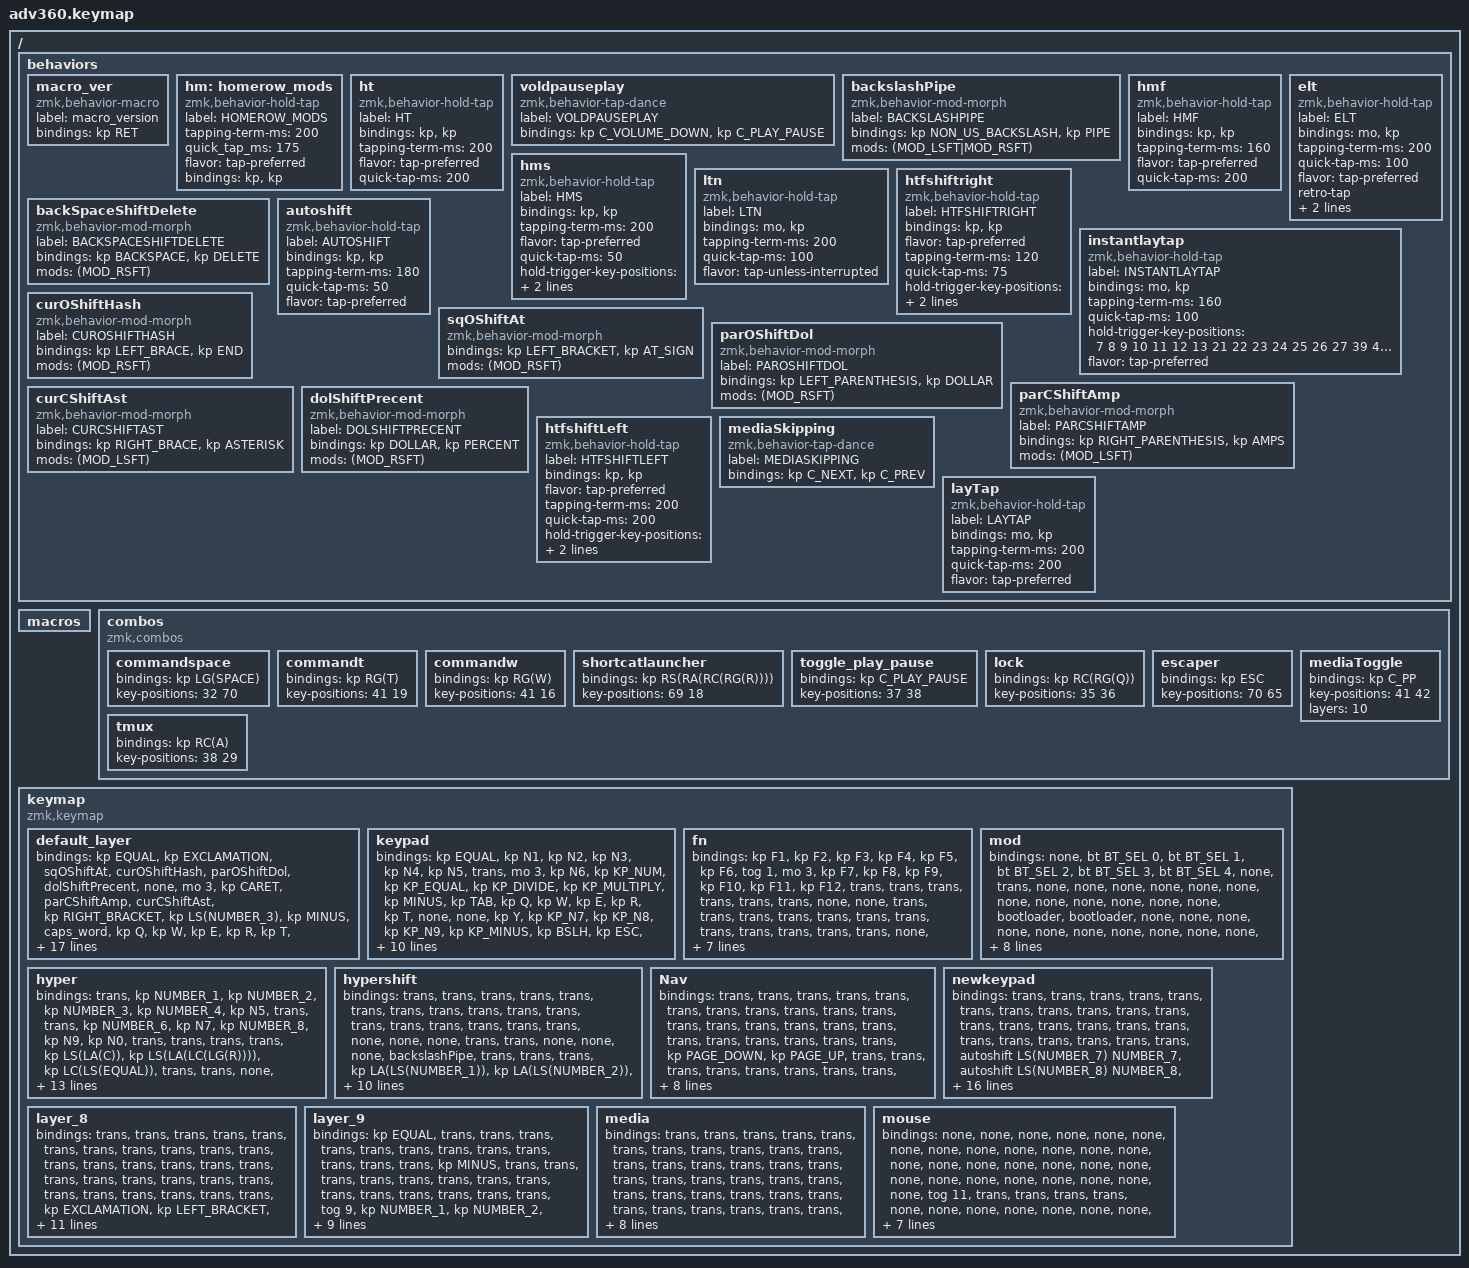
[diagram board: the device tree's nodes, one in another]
#define ZMK_POINTING_DEFAULT_MOVE_VAL 1200  // default: 600
#define ZMK_POINTING_DEFAULT_SCRL_VAL 20 // default: 10

#include <behaviors.dtsi>
#include <dt-bindings/zmk/backlight.h>
#include <dt-bindings/zmk/bt.h>
#include <dt-bindings/zmk/keys.h>
#include <dt-bindings/zmk/pointing.h>
#include <dt-bindings/zmk/rgb.h>

/ {
    behaviors {
        #include "macros.dtsi"
      #include "version.dtsi"
      #ifndef VERSION_MACRO

        macro_ver: macro_ver {
            compatible = "zmk,behavior-macro";
            label = "macro_version";
            #binding-cells = <0>;
            bindings = <&kp RET>;
        };

        #endif

        hm: homerow_mods {
            compatible = "zmk,behavior-hold-tap";
            label = "HOMEROW_MODS";
            #binding-cells = <2>;
            tapping-term-ms = <200>;
            quick_tap_ms = <175>;
            flavor = "tap-preferred";
            bindings = <&kp>, <&kp>;
        };

        ht: ht {
            compatible = "zmk,behavior-hold-tap";
            label = "HT";
            bindings = <&kp>, <&kp>;

            #binding-cells = <2>;
            tapping-term-ms = <200>;
            flavor = "tap-preferred";
            quick-tap-ms = <200>;
        };

        voldpauseplay: voldpauseplay {
            compatible = "zmk,behavior-tap-dance";
            label = "VOLDPAUSEPLAY";
            #binding-cells = <0>;
            bindings = <&kp C_VOLUME_DOWN>, <&kp C_PLAY_PAUSE>;
        };

        backslashPipe: backslashPipe {
            compatible = "zmk,behavior-mod-morph";
            label = "BACKSLASHPIPE";
            bindings = <&kp NON_US_BACKSLASH>, <&kp PIPE>;

            #binding-cells = <0>;
            mods = <(MOD_LSFT|MOD_RSFT)>;
        };

        hmf: hmf {
            compatible = "zmk,behavior-hold-tap";
            label = "HMF";
            bindings = <&kp>, <&kp>;

            #binding-cells = <2>;
            tapping-term-ms = <160>;
            flavor = "tap-preferred";
            quick-tap-ms = <200>;
        };

        hms: hms {
            compatible = "zmk,behavior-hold-tap";
            label = "HMS";
            bindings = <&kp>, <&kp>;

            #binding-cells = <2>;
            tapping-term-ms = <200>;
            flavor = "tap-preferred";
            quick-tap-ms = <50>;
            hold-trigger-key-positions = <7 7 8 9 10 11 12 21 22 23 24 25 26 39 40 41 42 43 44 54 55 56 57 58 71 72 73 74 13 27 45 59 75>;
            require-prior-idle-ms = <100>;
        };

        ltn: ltn {
            compatible = "zmk,behavior-hold-tap";
            label = "LTN";
            bindings = <&mo>, <&kp>;

            #binding-cells = <2>;
            tapping-term-ms = <200>;
            quick-tap-ms = <100>;
            flavor = "tap-unless-interrupted";
        };

        elt: elt {
            compatible = "zmk,behavior-hold-tap";
            label = "ELT";
            bindings = <&mo>, <&kp>;

            #binding-cells = <2>;
            tapping-term-ms = <200>;
            quick-tap-ms = <100>;
            flavor = "tap-preferred";
            retro-tap;
            hold-trigger-key-positions = <7 8 9 10 11 12 13 21 22 23 24 25 26 27 39 40 41 42 43 44 45 54 55 56 57 58 59 71 72 73 74 75>;
        };

        backSpaceShiftDelete: backSpaceShiftDelete {
            compatible = "zmk,behavior-mod-morph";
            label = "BACKSPACESHIFTDELETE";
            bindings = <&kp BACKSPACE>, <&kp DELETE>;

            #binding-cells = <0>;
            mods = <(MOD_RSFT)>;
        };

        htfshiftright: htfshiftright {
            compatible = "zmk,behavior-hold-tap";
            label = "HTFSHIFTRIGHT";
            bindings = <&kp>, <&kp>;

            #binding-cells = <2>;
            flavor = "tap-preferred";
            tapping-term-ms = <120>;
            quick-tap-ms = <75>;
            hold-trigger-key-positions = <0 1 2 3 4 5 6 14 15 16 17 18 19 20 28 29 30 31 32 33 34 35 36 46 47 48 49 50 51 52 60 61 62 63 64 65 66 67>;
            hold-trigger-on-release;
        };

        instantlaytap: instantlaytap {
            compatible = "zmk,behavior-hold-tap";
            label = "INSTANTLAYTAP";
            bindings = <&mo>, <&kp>;

            #binding-cells = <2>;
            tapping-term-ms = <160>;
            quick-tap-ms = <100>;
            hold-trigger-key-positions = <7 8 9 10 11 12 13 21 22 23 24 25 26 27 39 40 41 42 43 44 45 54 55 56 57 58 59 71 72 73 74 75 0 1 2 3 4 5 14 15 16 17 18 19 28 29 30 31 32 33 46 47 48 49 50 51 60 61 62 63 64 5 6 19 20 33 34 51 65>;
            flavor = "tap-preferred";
        };

        autoshift: autoshift {
            compatible = "zmk,behavior-hold-tap";
            label = "AUTOSHIFT";
            bindings = <&kp>, <&kp>;

            #binding-cells = <2>;
            tapping-term-ms = <180>;
            quick-tap-ms = <50>;
            flavor = "tap-preferred";
        };

        sqOShiftAt: sqOShiftAt {
            compatible = "zmk,behavior-mod-morph";
            bindings = <&kp LEFT_BRACKET>, <&kp AT_SIGN>;

            #binding-cells = <0>;
            mods = <(MOD_RSFT)>;
        };

        curOShiftHash: curOShiftHash {
            compatible = "zmk,behavior-mod-morph";
            label = "CUROSHIFTHASH";
            bindings = <&kp LEFT_BRACE>, <&kp END>;

            #binding-cells = <0>;
            mods = <(MOD_RSFT)>;
        };

        parOShiftDol: parOShiftDol {
            compatible = "zmk,behavior-mod-morph";
            label = "PAROSHIFTDOL";
            bindings = <&kp LEFT_PARENTHESIS>, <&kp DOLLAR>;

            #binding-cells = <0>;
            mods = <(MOD_RSFT)>;
        };

        parCShiftAmp: parCShiftAmp {
            compatible = "zmk,behavior-mod-morph";
            label = "PARCSHIFTAMP";
            bindings = <&kp RIGHT_PARENTHESIS>, <&kp AMPS>;

            #binding-cells = <0>;
            mods = <(MOD_LSFT)>;
        };

        curCShiftAst: curCShiftAst {
            compatible = "zmk,behavior-mod-morph";
            label = "CURCSHIFTAST";
            bindings = <&kp RIGHT_BRACE>, <&kp ASTERISK>;

            #binding-cells = <0>;
            mods = <(MOD_LSFT)>;
        };

        dolShiftPrecent: dolShiftPrecent {
            compatible = "zmk,behavior-mod-morph";
            label = "DOLSHIFTPRECENT";
            bindings = <&kp DOLLAR>, <&kp PERCENT>;

            #binding-cells = <0>;
            mods = <(MOD_RSFT)>;
        };

        htfshiftLeft: htfshiftLeft {
            compatible = "zmk,behavior-hold-tap";
            label = "HTFSHIFTLEFT";
            bindings = <&kp>, <&kp>;

            #binding-cells = <2>;
            flavor = "tap-preferred";
            tapping-term-ms = <200>;
            quick-tap-ms = <200>;
            hold-trigger-key-positions = <7 8 9 10 11 12 13 21 22 23 24 25 26 27 38 39 40 41 42 43 44 45 54 55 56 57 58 59 68 69 70 71 72 73 74 75 53 37>;
            hold-trigger-on-release;
        };

        mediaSkipping: mediaSkipping {
            compatible = "zmk,behavior-tap-dance";
            label = "MEDIASKIPPING";
            #binding-cells = <0>;
            bindings = <&kp C_NEXT>, <&kp C_PREV>;
        };

        layTap: layTap {
            compatible = "zmk,behavior-hold-tap";
            label = "LAYTAP";
            bindings = <&mo>, <&kp>;

            #binding-cells = <2>;
            tapping-term-ms = <200>;
            quick-tap-ms = <200>;
            flavor = "tap-preferred";
        };
    };

    macros {
    };

    combos {
        compatible = "zmk,combos";

        commandspace {
            bindings = <&kp LG(SPACE)>;
            key-positions = <32 70>;
        };

        commandt {
            bindings = <&kp RG(T)>;
            key-positions = <41 19>;
        };

        commandw {
            bindings = <&kp RG(W)>;
            key-positions = <41 16>;
        };

        shortcatlauncher {
            bindings = <&kp RS(RA(RC(RG(R))))>;
            key-positions = <69 18>;
        };

        toggle_play_pause {
            bindings = <&kp C_PLAY_PAUSE>;
            key-positions = <37 38>;
        };

        lock {
            bindings = <&kp RC(RG(Q))>;
            key-positions = <35 36>;
        };

        escaper {
            bindings = <&kp ESC>;
            key-positions = <70 65>;
        };

        mediaToggle {
            bindings = <&kp C_PP>;
            key-positions = <41 42>;
            layers = <10>;
        };

        tmux {
            bindings = <&kp RC(A)>;
            key-positions = <38 29>;
        };
    };

    keymap {
        compatible = "zmk,keymap";

        default_layer {
            bindings = <
&kp EQUAL   &kp EXCLAMATION             &sqOShiftAt         &curOShiftHash  &parOShiftDol       &dolShiftPrecent  &none                                                                                                  &mo 3      &kp CARET  &parCShiftAmp         &curCShiftAst    &kp RIGHT_BRACKET    &kp LS(NUMBER_3)                 &kp MINUS
&caps_word  &kp Q                       &kp W               &kp E           &kp R               &kp T             &kp EQUAL                                                                                              &kp MINUS  &kp Y      &kp U                 &kp I            &kp O                &kp P                            &kp BSLH
&elt 6 ESC  &htfshiftLeft LEFT_SHIFT A  &ht LEFT_CONTROL S  &ht LEFT_ALT D  &ht LEFT_COMMAND F  &elt 10 G         &kp F21                &kp LEFT_CONTROL  &kp C_VOLUME_DOWN      &kp RIGHT_ALT  &kp RCTRL               &none      &kp H      &hmf RIGHT_COMMAND J  &ht RIGHT_ALT K  &ht RIGHT_CONTROL L  &htfshiftright RIGHT_SHIFT SEMI  &kp SQT
&mo 7       &kp Z                       &kp X               &kp C           &kp V               &kp B                                                      &kp C_VOLUME_UP        &mo 9                                             &kp N      &kp M                 &kp COMMA        &kp DOT              &kp FSLH                         &kp RSHFT
&mo 2       &kp GRAVE                   &none               &kp LEFT        &kp RIGHT_ARROW                       &backSpaceShiftDelete  &kp TAB           &tog 11                &tog 9         &instantlaytap 4 ENTER  &kp SPACE             &kp DOWN_ARROW        &kp UP_ARROW     &none                &none                            &mo 2
            >;
        };

        keypad {
            bindings = <
&kp EQUAL  &kp N1     &kp N2    &kp N3    &kp N4     &kp N5  &trans                                                   &mo 3      &kp N6  &kp KP_NUM  &kp KP_EQUAL  &kp KP_DIVIDE  &kp KP_MULTIPLY  &kp MINUS
&kp TAB    &kp Q      &kp W     &kp E     &kp R      &kp T   &none                                                    &none      &kp Y   &kp KP_N7   &kp KP_N8     &kp KP_N9      &kp KP_MINUS     &kp BSLH
&kp ESC    &kp A      &kp S     &kp D     &kp F      &kp G   &none     &kp LCTRL  &kp LALT      &kp LGUI   &kp RCTRL  &none      &kp H   &kp KP_N4   &kp KP_N5     &kp KP_N6      &kp KP_PLUS      &kp SQT
&kp LSHFT  &kp Z      &kp X     &kp C     &kp V      &kp B                        &kp HOME      &kp PG_UP                        &kp N   &kp KP_N1   &kp KP_N2     &kp KP_N3      &kp KP_ENTER     &kp RSHFT
&mo 2      &kp GRAVE  &kp CAPS  &kp LEFT  &kp RIGHT          &kp BSPC  &kp DEL    &kp END       &kp PG_DN  &kp ENTER  &kp KP_N0          &kp UP      &kp DOWN      &kp KP_DOT     &kp RBKT         &mo 2
            >;
        };

        fn {
            bindings = <
&kp F1  &kp F2  &kp F3  &kp F4  &kp F5  &kp F6  &tog 1                                      &mo 3   &kp F7  &kp F8  &kp F9  &kp F10  &kp F11  &kp F12
&trans  &trans  &trans  &trans  &trans  &trans  &none                                       &none   &trans  &trans  &trans  &trans   &trans   &trans
&trans  &trans  &trans  &trans  &trans  &trans  &none   &trans  &trans      &trans  &trans  &none   &trans  &trans  &trans  &trans   &trans   &trans
&trans  &trans  &trans  &trans  &trans  &trans                  &trans      &trans                  &trans  &trans  &trans  &trans   &trans   &trans
&trans  &trans  &trans  &trans  &trans          &trans  &trans  &trans      &trans  &trans  &trans          &trans  &trans  &trans   &trans   &trans
            >;
        };

        mod {
            bindings = <
&none  &bt BT_SEL 0  &bt BT_SEL 1  &bt BT_SEL 2  &bt BT_SEL 3  &bt BT_SEL 4  &none                                                  &trans                  &none  &none       &none       &none  &none  &none
&none  &none         &none         &none         &none         &none         &bootloader                                            &bootloader             &none  &none       &none       &none  &none  &none
&none  &none         &none         &none         &none         &none         &none        &none  &none      &bt BT_CLR  &none       &rgb_ug RGB_MEFS_CMD 5  &none  &none       &none       &none  &none  &none
&none  &none         &none         &none         &macro_ver    &none                             &none      &none                                           &none  &none       &none       &none  &none  &none
&none  &none         &none         &none         &none                       &none        &none  &none      &none       &bl BL_TOG  &rgb_ug RGB_TOG                &bl BL_INC  &bl BL_DEC  &none  &none  &none
            >;
        };

        hyper {
            bindings = <
&trans       &kp NUMBER_1      &kp NUMBER_2      &kp NUMBER_3      &kp NUMBER_4           &kp N5             &trans                                           &trans  &kp NUMBER_6  &kp N7                &kp NUMBER_8           &kp N9            &kp N0            &trans
&trans       &trans            &trans            &kp LS(LA(C))     &kp LS(LA(LC(LG(R))))  &kp LC(LS(EQUAL))  &trans                                           &trans  &none         &kp LG(LEFT_BRACKET)  &kp RG(RIGHT_BRACKET)  &none             &trans            &trans
&kp RA(TAB)  &kp LA(NUMBER_1)  &kp LA(NUMBER_2)  &kp LA(NUMBER_3)  &kp LA(NUMBER_4)       &trans             &trans  &trans       &trans      &trans  &trans  &trans  &trans        &kp LA(NUMBER_5)      &kp LA(NUMBER_6)       &kp LA(NUMBER_7)  &kp LA(NUMBER_8)  &trans
&trans       &trans            &trans            &trans            &trans                 &trans                                  &trans      &trans                  &trans        &none                 &trans                 &trans            &trans            &trans
&trans       &trans            &trans            &trans            &trans                                    &mo 5   &kp LA(TAB)  &trans      &trans  &trans  &trans                &trans                &trans                 &trans            &trans            &trans
            >;
        };

        hypershift {
            bindings = <
&trans  &trans                &trans                &trans                &trans                &trans  &trans                                      &trans  &trans  &trans                &trans                &trans                &trans                &trans
&trans  &trans                &trans                &none                 &none                 &none   &trans                                      &trans  &none   &none                 &none                 &backslashPipe        &trans                &trans
&trans  &kp LA(LS(NUMBER_1))  &kp LA(LS(NUMBER_2))  &kp LA(LS(NUMBER_3))  &kp LA(LS(NUMBER_4))  &trans  &trans  &trans  &trans      &trans  &trans  &trans  &trans  &kp LA(LS(NUMBER_5))  &kp LA(LS(NUMBER_6))  &kp LA(LS(NUMBER_7))  &kp LA(LS(NUMBER_8))  &trans
&trans  &trans                &trans                &trans                &trans                &trans                  &trans      &trans                  &trans  &trans                &trans                &trans                &trans                &trans
&trans  &trans                &trans                &trans                &trans                        &trans  &trans  &trans      &trans  &trans  &trans          &trans                &trans                &trans                &trans                &trans
            >;
        };

        Nav {
            bindings = <
&trans  &trans  &trans  &trans  &trans  &trans  &trans                                      &trans  &trans    &trans         &trans       &trans     &trans  &trans
&trans  &trans  &trans  &trans  &trans  &trans  &trans                                      &trans  &trans    &kp PAGE_DOWN  &kp PAGE_UP  &trans     &trans  &trans
&trans  &trans  &trans  &trans  &trans  &trans  &trans  &trans  &trans      &trans  &trans  &trans  &kp LEFT  &kp DOWN       &kp UP       &kp RIGHT  &trans  &trans
&trans  &trans  &trans  &trans  &trans  &trans                  &trans      &trans                  &trans    &trans         &trans       &trans     &trans  &trans
&trans  &trans  &trans  &trans  &trans          &trans  &trans  &trans      &trans  &trans  &trans            &trans         &trans       &trans     &trans  &trans
            >;
        };

        newkeypad {
            bindings = <
&trans  &trans  &trans  &trans  &trans  &trans  &trans                                      &trans  &trans  &trans                            &trans                            &trans                            &trans  &trans
&trans  &trans  &trans  &trans  &trans  &trans  &trans                                      &trans  &trans  &autoshift LS(NUMBER_7) NUMBER_7  &autoshift LS(NUMBER_8) NUMBER_8  &autoshift LS(NUMBER_9) NUMBER_9  &trans  &trans
&trans  &trans  &trans  &trans  &trans  &trans  &trans  &trans  &trans      &trans  &trans  &trans  &trans  &autoshift LS(NUMBER_4) NUMBER_4  &autoshift LS(NUMBER_5) NUMBER_5  &autoshift LS(NUMBER_6) NUMBER_6  &trans  &trans
&trans  &trans  &trans  &trans  &trans  &trans                  &trans      &trans                  &trans  &autoshift LS(NUMBER_1) NUMBER_1  &autoshift LS(NUMBER_2) NUMBER_2  &autoshift END NUMBER_3           &trans  &trans
&trans  &trans  &trans  &trans  &trans          &trans  &trans  &trans      &trans  &trans  &trans          &trans                            &autoshift LS(NUMBER_0) NUMBER_0  &trans                            &trans  &trans
            >;
        };

        layer_8 {
            bindings = <
&trans  &trans           &trans            &trans          &trans                &trans      &trans                                      &trans  &trans        &trans                 &trans           &trans             &trans  &trans
&trans  &trans           &trans            &trans          &trans                &trans      &trans                                      &trans  &trans        &trans                 &trans           &trans             &trans  &trans
&trans  &kp EXCLAMATION  &kp LEFT_BRACKET  &kp LEFT_BRACE  &kp LEFT_PARENTHESIS  &kp DOLLAR  &trans  &trans  &trans      &trans  &trans  &trans  &kp CARET     &kp RIGHT_PARENTHESIS  &kp RIGHT_BRACE  &kp RIGHT_BRACKET  &trans  &trans
&trans  &kp NUMBER_1     &kp NUMBER_2      &kp NUMBER_3    &kp NUMBER_4          &kp N5                      &trans      &trans                  &kp NUMBER_6  &kp N7                 &kp N8           &kp N9             &kp N0  &trans
&trans  &trans           &trans            &trans          &trans                            &trans  &trans  &trans      &trans  &trans  &trans                &trans                 &trans           &trans             &trans  &trans
            >;
        };

        layer_9 {
            bindings = <
&kp EQUAL  &trans        &trans        &trans        &trans        &trans        &trans                                      &trans  &trans        &trans        &trans        &trans      &trans        &kp MINUS
&trans     &trans        &trans        &trans        &trans        &trans        &trans                                      &trans  &trans        &trans        &trans        &trans      &trans        &trans
&tog 9     &kp NUMBER_1  &kp NUMBER_2  &kp NUMBER_3  &kp NUMBER_4  &kp NUMBER_5  &trans  &trans  &trans      &trans  &trans  &trans  &kp NUMBER_6  &kp NUMBER_7  &kp NUMBER_8  &kp N9      &kp NUMBER_0  &trans
&trans     &trans        &trans        &trans        &trans        &trans                        &trans      &trans                  &trans        &trans        &kp COMMA     &kp PERIOD  &kp SLASH     &trans
&trans     &trans        &trans        &trans        &trans                      &trans  &trans  &trans      &trans  &trans  &trans                &trans        &trans        &trans      &trans        &trans
            >;
        };

        media {
            bindings = <
&trans  &trans  &trans  &trans  &trans  &trans  &trans                                      &trans  &trans      &trans             &trans           &trans      &trans  &trans
&trans  &trans  &trans  &trans  &trans  &trans  &trans                                      &trans  &trans      &trans             &trans           &trans      &trans  &trans
&trans  &trans  &trans  &trans  &trans  &trans  &trans  &trans  &trans      &trans  &trans  &trans  &kp C_PREV  &kp C_VOLUME_DOWN  &kp C_VOLUME_UP  &kp C_NEXT  &trans  &trans
&trans  &trans  &trans  &trans  &trans  &trans                  &trans      &trans                  &trans      &trans             &trans           &trans      &trans  &trans
&trans  &trans  &trans  &trans  &trans          &trans  &trans  &trans      &trans  &trans  &trans              &trans             &trans           &trans      &trans  &trans
            >;
        };

        mouse {
            bindings = <
&none    &none   &none   &none   &none   &none  &none                                      &none      &none           &none           &none         &none            &none  &none
&none    &none   &none   &none   &none   &none  &none                                      &none      &none           &none           &none         &none            &none  &none
&tog 11  &trans  &trans  &trans  &trans  &none  &none      &none  &none      &none  &none  &none      &mmv MOVE_LEFT  &mmv MOVE_DOWN  &mmv MOVE_UP  &mmv MOVE_RIGHT  &none  &none
&none    &none   &none   &none   &none   &none                    &none      &none                    &none           &none           &none         &none            &none  &none
&none    &none   &none   &none   &none          &mkp RCLK  &none  &none      &none  &none  &mkp LCLK                  &none           &none         &none            &none  &none
            >;
        };
    };
};
